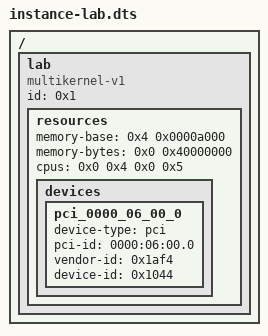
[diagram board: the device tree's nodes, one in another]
/dts-v1/;

/ {
    lab {
        compatible = "multikernel-v1";
        id = <0x1>;
        resources {
            memory-base = <0x4 0x0000a000>;
            memory-bytes = <0x0 0x40000000>;
            cpus = <0x0 0x4 0x0 0x5>;
            devices {
                pci_0000_06_00_0 {
                    device-type = "pci";
                    pci-id = "0000:06:00.0";
                    vendor-id = <0x1af4>;
                    device-id = <0x1044>;
                };
            };
        };
    };
};
